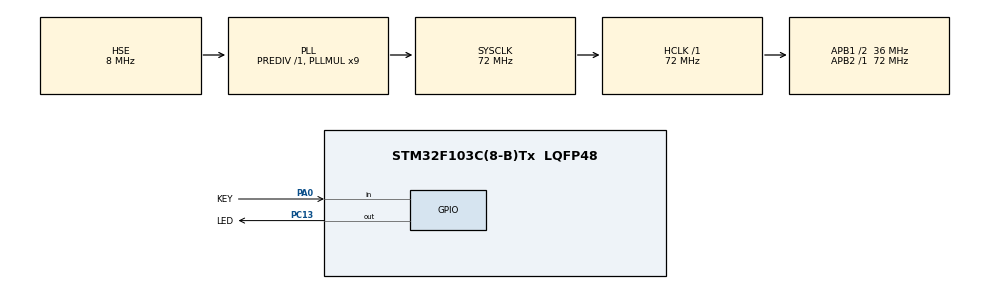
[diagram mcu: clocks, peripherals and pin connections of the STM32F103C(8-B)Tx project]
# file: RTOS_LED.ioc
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FREERTOS.Queues01=LEDStatus,16,osThreadState_t,0,Dynamic,NULL,NULL
FREERTOS.Tasks01=LEDTask,24,128,Task_LED,Default,NULL,Dynamic,NULL,NULL;PrintTask,24,256,Task_Print,Default,NULL,Dynamic,NULL,NULL;KeyTask,25,128,Task_Key,Default,NULL,Dynamic,NULL,NULL
Mcu.Family=STM32F1
Mcu.Name=STM32F103C(8-B)Tx
Mcu.Package=LQFP48
NVIC.PriorityGroup=NVIC_PRIORITYGROUP_4
NVIC.TIM4_IRQn=true\:15\:0\:false\:false\:true\:false\:false\:true\:true
NVIC.TimeBase=TIM4_IRQn
NVIC.TimeBaseIP=TIM4
PA0-WKUP.GPIO_Label=KEY
PA0-WKUP.GPIO_PuPd=GPIO_PULLUP
PA0-WKUP.Signal=GPIO_Input
PA13.Mode=Serial_Wire
PA13.Signal=SYS_JTMS-SWDIO
PA14.Mode=Serial_Wire
PA14.Signal=SYS_JTCK-SWCLK
PC13-TAMPER-RTC.GPIO_Label=LED
PC13-TAMPER-RTC.PinState=GPIO_PIN_SET
PC13-TAMPER-RTC.Signal=GPIO_Output
PC14-OSC32_IN.Mode=LSE-External-Oscillator
PC14-OSC32_IN.Signal=RCC_OSC32_IN
PC15-OSC32_OUT.Mode=LSE-External-Oscillator
PC15-OSC32_OUT.Signal=RCC_OSC32_OUT
PD0-OSC_IN.Mode=HSE-External-Oscillator
PD0-OSC_IN.Signal=RCC_OSC_IN
PD1-OSC_OUT.Mode=HSE-External-Oscillator
PD1-OSC_OUT.Signal=RCC_OSC_OUT
ProjectManager.HeapSize=0x200
ProjectManager.StackSize=0x400
ProjectManager.TargetToolchain=MDK-ARM V5.32
RCC.AHBFreq_Value=72000000
RCC.APB1CLKDivider=RCC_HCLK_DIV2
RCC.APB1Freq_Value=36000000
RCC.APB1TimFreq_Value=72000000
RCC.APB2Freq_Value=72000000
RCC.APB2TimFreq_Value=72000000
RCC.HCLKFreq_Value=72000000
RCC.PLLMUL=RCC_PLL_MUL9
RCC.PLLSourceVirtual=RCC_PLLSOURCE_HSE
RCC.SYSCLKFreq_VALUE=72000000
RCC.SYSCLKSource=RCC_SYSCLKSOURCE_PLLCLK
RCC.USBFreq_Value=72000000
VP_FREERTOS_VS_CMSIS_V2.Mode=CMSIS_V2
VP_SYS_VS_tim4.Mode=TIM4
board=custom

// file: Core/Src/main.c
/* USER CODE BEGIN Header */
/**
 ******************************************************************************
 * @file           : main.c
 * @brief          : Main program body
 ******************************************************************************
 * @attention
 *
 * Copyright (c) 2022 STMicroelectronics.
 * All rights reserved.
 *
 * This software is licensed under terms that can be found in the LICENSE file
 * in the root directory of this software component.
 * If no LICENSE file comes with this software, it is provided AS-IS.
 *
 ******************************************************************************
 */
/* USER CODE END Header */
#include "main.h"
#include "cmsis_os.h"
#include "gpio.h"

/* USER CODE BEGIN Includes */
#include "log.h"
/* USER CODE END Includes */

void SystemClock_Config(void);
void MX_FREERTOS_Init(void);

int main(void)
{

  /* MCU Configuration--------------------------------------------------------*/

  /* Reset of all peripherals, Initializes the Flash interface and the Systick. */
  HAL_Init();

  /* Configure the system clock */
  SystemClock_Config();

  /* Initialize all configured peripherals */
  MX_GPIO_Init();

  /* Init scheduler */
  osKernelInitialize();  /* Call init function for freertos objects (in freertos.c) */
  MX_FREERTOS_Init();

  /* Start scheduler */
  osKernelStart();

  /* We should never get here as control is now taken by the scheduler */
  /* Infinite loop */
    while (1)
    {

    }
}

void SystemClock_Config(void)
{
  RCC_OscInitTypeDef RCC_OscInitStruct = {0};
  RCC_ClkInitTypeDef RCC_ClkInitStruct = {0};

  /** Initializes the RCC Oscillators according to the specified parameters
  * in the RCC_OscInitTypeDef structure.
  */
  RCC_OscInitStruct.OscillatorType = RCC_OSCILLATORTYPE_HSE;
  RCC_OscInitStruct.HSEState = RCC_HSE_ON;
  RCC_OscInitStruct.HSEPredivValue = RCC_HSE_PREDIV_DIV1;
  RCC_OscInitStruct.HSIState = RCC_HSI_ON;
  RCC_OscInitStruct.PLL.PLLState = RCC_PLL_ON;
  RCC_OscInitStruct.PLL.PLLSource = RCC_PLLSOURCE_HSE;
  RCC_OscInitStruct.PLL.PLLMUL = RCC_PLL_MUL9;
  if (HAL_RCC_OscConfig(&RCC_OscInitStruct) != HAL_OK)
  {
    Error_Handler();
  }

  /** Initializes the CPU, AHB and APB buses clocks
  */
  RCC_ClkInitStruct.ClockType = RCC_CLOCKTYPE_HCLK|RCC_CLOCKTYPE_SYSCLK
                              |RCC_CLOCKTYPE_PCLK1|RCC_CLOCKTYPE_PCLK2;
  RCC_ClkInitStruct.SYSCLKSource = RCC_SYSCLKSOURCE_PLLCLK;
  RCC_ClkInitStruct.AHBCLKDivider = RCC_SYSCLK_DIV1;
  RCC_ClkInitStruct.APB1CLKDivider = RCC_HCLK_DIV2;
  RCC_ClkInitStruct.APB2CLKDivider = RCC_HCLK_DIV1;

  if (HAL_RCC_ClockConfig(&RCC_ClkInitStruct, FLASH_LATENCY_2) != HAL_OK)
  {
    Error_Handler();
  }
}

void HAL_TIM_PeriodElapsedCallback(TIM_HandleTypeDef *htim)
{
  if (htim->Instance == TIM4) {
    HAL_IncTick();
  }
}

void Error_Handler(void)
{
    __disable_irq();
    while (1)
    {
    }
}

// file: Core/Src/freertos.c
/* USER CODE BEGIN Header */
/**
 ******************************************************************************
 * File Name          : freertos.c
 * Description        : Code for freertos applications
 ******************************************************************************
 * @attention
 *
 * Copyright (c) 2022 STMicroelectronics.
 * All rights reserved.
 *
 * This software is licensed under terms that can be found in the LICENSE file
 * in the root directory of this software component.
 * If no LICENSE file comes with this software, it is provided AS-IS.
 *
 ******************************************************************************
 */
/* USER CODE END Header */

#include "FreeRTOS.h"
#include "task.h"
#include "main.h"
#include "cmsis_os.h"

/* USER CODE BEGIN Includes */
#include "log.h"
/* USER CODE END Includes */

/* Definitions for LEDTask */
osThreadId_t LEDTaskHandle;
const osThreadAttr_t LEDTask_attributes = {
    .name = "LEDTask",
    .stack_size = 128 * 4,
    .priority = (osPriority_t)osPriorityNormal,
};
/* Definitions for PrintTask */
osThreadId_t PrintTaskHandle;
const osThreadAttr_t PrintTask_attributes = {
    .name = "PrintTask",
    .stack_size = 256 * 4,
    .priority = (osPriority_t)osPriorityNormal,
};
/* Definitions for KeyTask */
osThreadId_t KeyTaskHandle;
const osThreadAttr_t KeyTask_attributes = {
    .name = "KeyTask",
    .stack_size = 128 * 4,
    .priority = (osPriority_t)osPriorityNormal1,
};
/* Definitions for LEDStatus */
osMessageQueueId_t LEDStatusHandle;
const osMessageQueueAttr_t LEDStatus_attributes = {
    .name = "LEDStatus"};

void Task_LED(void *argument);
void Task_Print(void *argument);
void Task_Key(void *argument);

void MX_FREERTOS_Init(void); /* (MISRA C 2004 rule 8.1) */

void MX_FREERTOS_Init(void)
{

    /* Create the queue(s) */
    /* creation of LEDStatus */
    LEDStatusHandle = osMessageQueueNew(16, sizeof(osThreadState_t), &LEDStatus_attributes);

    /* Create the thread(s) */
    /* creation of LEDTask */
    LEDTaskHandle = osThreadNew(Task_LED, NULL, &LEDTask_attributes);

    /* creation of PrintTask */
    PrintTaskHandle = osThreadNew(Task_Print, NULL, &PrintTask_attributes);

    /* creation of KeyTask */
    KeyTaskHandle = osThreadNew(Task_Key, NULL, &KeyTask_attributes);

}

void Task_LED(void *argument)
{
    /* USER CODE BEGIN Task_LED */

    uint32_t PreviousWakeTime = osKernelGetTickCount();
    osThreadState_t LED_status = osThreadInactive;
    osStatus_t os_status;

    /* Infinite loop */
    for (;;)
    {
        LED_status = osThreadGetState(LEDTaskHandle);
        os_status = osMessageQueuePut(LEDStatusHandle, &LED_status, NULL, 0);
        if (os_status != osOK)
        {
            LOGE("osMessageQueuePut is not OK");
        }

        HAL_GPIO_TogglePin(LED_GPIO_Port, LED_Pin);
        osDelayUntil(PreviousWakeTime += 1000);
    }
    /* USER CODE END Task_LED */
}

void Task_Print(void *argument)
{
    /* USER CODE BEGIN Task_Print */

    uint32_t PreviousWakeTime = osKernelGetTickCount();
    osThreadState_t LED_status = osThreadInactive;
    osStatus_t os_status;

    /* Infinite loop */
    for (;;)
    {
        os_status = osMessageQueueGet(LEDStatusHandle, &LED_status, NULL, 0);
        if (os_status == osOK)
        {
            switch (LED_status)
            {
                case osThreadRunning:
                    LOGI("Task is Running");
                    break;
                case osThreadReady:
                    LOGI("Task is Ready");
                    break;
                case osThreadBlocked:
                    LOGI("Task is Blocked");
                    break;
                case osThreadTerminated:
                    LOGI("Task is Terminated");
                    break;
                case osThreadInactive:
                    LOGE("Task is Inactive");
                    break;
                case osThreadReserved:
                    LOGE("Task is Reserved");
                    break;
                case osThreadError:
                    LOGE("Task is Error");
                    break;
            }
        }
        else
        {
            LOGE("osMessageQueueGet is not OK");
        }
        osDelayUntil(PreviousWakeTime += 1000);
    }
    /* USER CODE END Task_Print */
}

void Task_Key(void *argument)
{
    /* USER CODE BEGIN Task_Key */

    osThreadState_t LED_status = osThreadRunning;

    /* Infinite loop */
    for (;;)
    {
        if (HAL_GPIO_ReadPin(KEY_GPIO_Port, KEY_Pin) == GPIO_PIN_RESET)
        {
            osDelay(20);
            if (HAL_GPIO_ReadPin(KEY_GPIO_Port, KEY_Pin) == GPIO_PIN_RESET)
            {
                switch (LED_status)
                {
                    case osThreadRunning:
                        osThreadSuspend(LEDTaskHandle);
                        LED_status = osThreadInactive;
                        break;
                    case osThreadInactive:
                        osThreadResume(LEDTaskHandle);
                        LED_status = osThreadRunning;
                        break;
                    default:
                        break;
                }
            }
        }

        osDelay(10);
    }
    /* USER CODE END Task_Key */
}
